# PIC32CK1025GC00100 device description
Architecture: CORTEX-M33; Family: PIC32CK; Series: PIC32CKGC00
Registers are 32-bit, read-write, reset 0x0 unless marked. A register's access mark holds for its fields unless they carry their own. Offsets are from the block's base; [hi:lo] are bit positions; lines under a group give offsets from that group; {n}, {i} and the like mark numbered series; 'fields as' and 'values as' point back to an identical list; <NAME> marks a mode.

## SIG — Software Interrupt Generation
Instances: SIG 0xE000EF00
0x00 STIR wo reset not defined — Software Triggered Interrupt Register
  [8:0] INTID — Interrupt ID to be pended

## SQI_DESCRIPTOR — Polaris Serial Quad Interface SIB
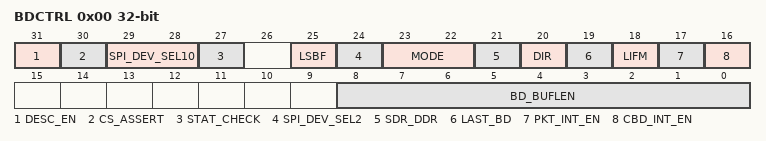
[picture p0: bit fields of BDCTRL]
0x00 BDCTRL reset not defined — Buffer Descriptor Control Register
  [31] DESC_EN — Descriptor Enable
  [30] CS_ASSERT — Chip Select Assert/Deassert
  [29:28] SPI_DEV_SEL10 — SPI Device Select bits 1:0
  [27] STAT_CHECK — Status Check
  [25] LSBF — Data format on SPI Data Lanes
  [24] SPI_DEV_SEL2 — SPI Device Select bit 2
  [23:22] MODE — Based on the mode, the controller has to transmit or receive the data in one or two or 4 lanes
  [21] SDR_DDR — SDR or DDR mode
  [20] DIR — Direction of data transfer.
  [19] LAST_BD — Last Buffer Descriptors.
  [18] LIFM — Indicates last data of the packet.
  [17] PKT_INT_EN — Generate Interrupt after processing the current buffer descriptor, if it is the end of the packet.
  [16] CBD_INT_EN — Generate Interrupt after processing the current buffer descriptor
  [8:0] BD_BUFLEN — Buffer Descriptor Length
0x04 BDSTATUS reset not defined — Buffer Descriptor Status Register
0x08 BDADDR reset not defined — Buffer Descriptor Address Register
0x0C BDNXTPTR reset not defined — Buffer Descriptor Next Pointer Register

## SysTick — SysTick Timer
Instances: SysTick 0xE000E010
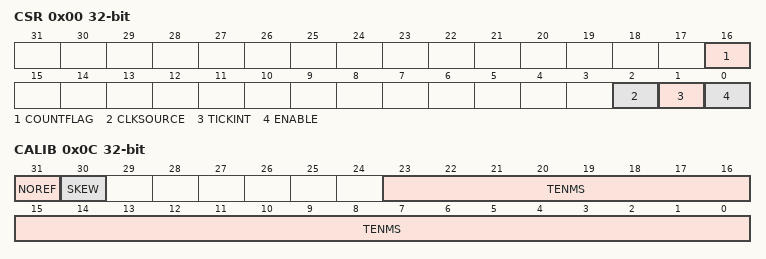
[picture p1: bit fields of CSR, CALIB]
0x00 CSR reset not defined — SysTick Control and Status Register
  [16] COUNTFLAG
  [2] CLKSOURCE — Clock source
  [1] TICKINT — Tick interrupt
  [0] ENABLE — SysTick enable
0x04 RVR reset not defined — SysTick Reload Value Register
  [24] RELOAD — Counter reload value
0x08 CVR reset not defined — SysTick Current Value Register
  [24] CURRENT — Current counter value
0x0C CALIB ro reset not defined — SysTick Calibration Value Register
  [31] NOREF — No reference
  [30] SKEW
  [23:0] TENMS — Ten milliseconds

## TRAM — TrustRAM
Instances: TRAM 0x4401E000
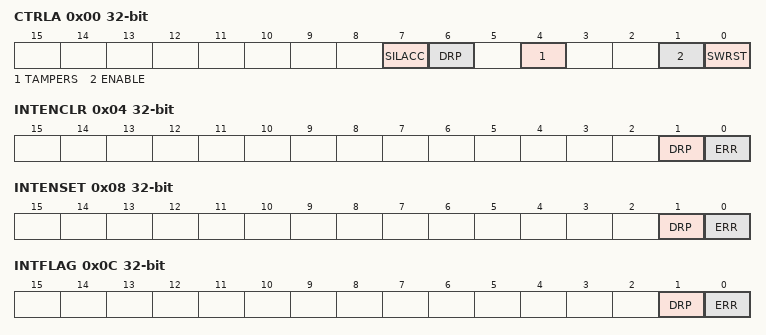
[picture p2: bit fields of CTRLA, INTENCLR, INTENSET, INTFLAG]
0x00 CTRLA — Control
  [7] SILACC — Silent Access
  [6] DRP — Data Remanence Prevention
  [4] TAMPERS — Tamper Erase
  [1] ENABLE
  [0] SWRST — Software Reset
0x04 INTENCLR (atomic clear) — Interrupt Enable Clear
  [1] DRP — Data Remanence Prevention Ended Interrupt Enable
  [0] ERR — TrustRAM Readout Error Interrupt Enable
0x08 INTENSET (atomic set) — Interrupt Enable Set
  fields as INTENCLR
0x0C INTFLAG (atomic clear) — Interrupt Flag Status and Clear
  [1] DRP — Data Remanence Prevention Ended
  [0] ERR — TrustRAM Readout Error
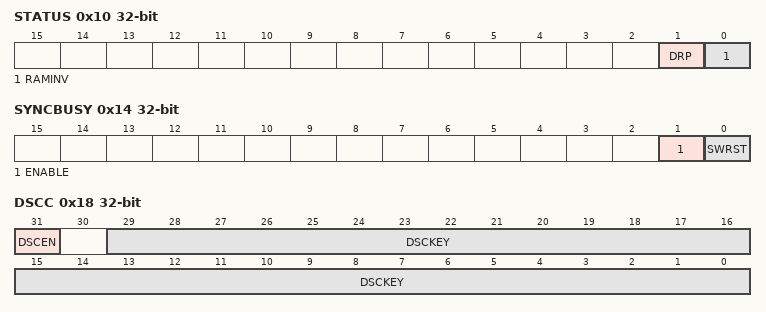
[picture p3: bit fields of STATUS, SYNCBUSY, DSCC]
0x10 STATUS ro
  [1] DRP — Data Remanence Prevention Ongoing
  [0] RAMINV — RAM Inversion Bit
0x14 SYNCBUSY ro — Synchronization Busy Status
  [1] ENABLE — Enable Busy
  [0] SWRST — Software Reset Busy
0x18 DSCC wo — Data Scramble Control
  [31] DSCEN — Data Scramble Enable
  [29:0] DSCKEY — Data Scramble Key
0x1C PERMW wo — Permutation Write
  [2:0] DATA — Permutation Scrambler Data Input
0x20 PERMR ro — Permutation Read
  [2:0] DATA — Permutation Scrambler Data Output
{0x1000+4i} RAM[{i}] (i=0..2047) — TrustRAM
  [31:0] DATA — Trust RAM Data

## TRNG — True Random Generator
Instances: TRNG 0x45024000
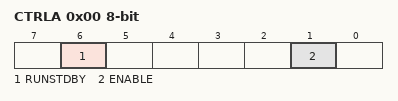
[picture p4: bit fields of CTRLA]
0x00 CTRLA 8-bit — Control A
  [6] RUNSTDBY — Run in Standby
  [1] ENABLE
0x04 EVCTRL 8-bit — Event Control
  [0] DATARDYEO — Data Ready Event Output
0x08 INTENCLR 8-bit (atomic clear) — Interrupt Enable Clear
  [0] DATARDY — Data Ready Interrupt Enable
0x09 INTENSET 8-bit (atomic set) — Interrupt Enable Set
  [0] DATARDY — Data Ready Interrupt Enable
0x0A INTFLAG 8-bit (atomic clear) — Interrupt Flag Status and Clear
  [0] DATARDY — Data Ready Interrupt Flag
0x20 DATA ro reset not defined — Output Data

## USB_DESCRIPTOR — Full-Speed Universal Serial Bus
Modes: DEVICE when USB.CTRLA.MODE=0 (USB is Device); HOST when USB.CTRLA.MODE=1 (USB is Host)
{0x0+0x10*i} DEVICE_DESC_BANK[{i}] (i=0..1) <DEVICE> group
  0x00 ADDR <DEVICE> reset not defined — DEVICE_DESC_BANK Endpoint Bank, Adress of Data Buffer
    [31:0] ADDR — Adress of data buffer
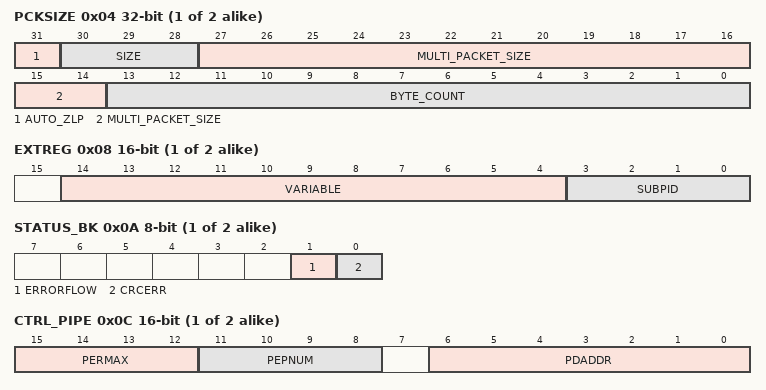
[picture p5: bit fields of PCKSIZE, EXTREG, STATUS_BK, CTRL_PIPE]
  0x04 PCKSIZE <DEVICE> reset not defined — DEVICE_DESC_BANK Endpoint Bank, Packet Size
    [31] AUTO_ZLP — Automatic Zero Length Packet
    [30:28] SIZE — Enpoint size
    [27:14] MULTI_PACKET_SIZE — Multi Packet In or Out size
    [13:0] BYTE_COUNT
  0x08 EXTREG <DEVICE> 16-bit reset not defined — DEVICE_DESC_BANK Endpoint Bank, Extended
    [14:4] VARIABLE — Variable field send with extended token
    [3:0] SUBPID — SUBPID field send with extended token
  0x0A STATUS_BK <DEVICE> 8-bit reset not defined — DEVICE_DESC_BANK Enpoint Bank, Status of Bank
    [1] ERRORFLOW — Error Flow Status
    [0] CRCERR — CRC Error Status
{0x0+0x10*i} HOST_DESC_BANK[{i}] (i=0..1) <HOST> group
  0x00 ADDR <HOST> reset not defined — HOST_DESC_BANK Host Bank, Adress of Data Buffer
    [31:0] ADDR — Adress of data buffer
  0x04 PCKSIZE <HOST> reset not defined — HOST_DESC_BANK Host Bank, Packet Size
    [31] AUTO_ZLP — Automatic Zero Length Packet
    [30:28] SIZE — Pipe size
    [27:14] MULTI_PACKET_SIZE — Multi Packet In or Out size
    [13:0] BYTE_COUNT
  0x08 EXTREG <HOST> 16-bit reset not defined — HOST_DESC_BANK Host Bank, Extended
    fields as DEVICE_DESC_BANK[0]<DEVICE>.EXTREG<DEVICE>
  0x0A STATUS_BK <HOST> 8-bit reset not defined — HOST_DESC_BANK Host Bank, Status of Bank
    [1] ERRORFLOW — Error Flow Status
    [0] CRCERR — CRC Error Status
  0x0C CTRL_PIPE <HOST> 16-bit — HOST_DESC_BANK Host Bank, Host Control Pipe
    [15:12] PERMAX — Pipe Error Max Number
    [11:8] PEPNUM — Pipe Endpoint Number
    [6:0] PDADDR — Pipe Device Adress
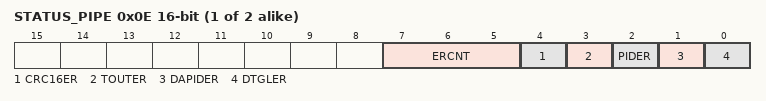
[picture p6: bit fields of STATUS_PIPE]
  0x0E STATUS_PIPE <HOST> 16-bit reset not defined — HOST_DESC_BANK Host Bank, Host Status Pipe
    [7:5] ERCNT — Pipe Error Count
    [4] CRC16ER — CRC16 Error
    [3] TOUTER — Time Out Error
    [2] PIDER — PID Error
    [1] DAPIDER — Data PID Error
    [0] DTGLER — Data Toggle Error

## WDT — Watchdog Timer
Instances: WDT 0x44016000
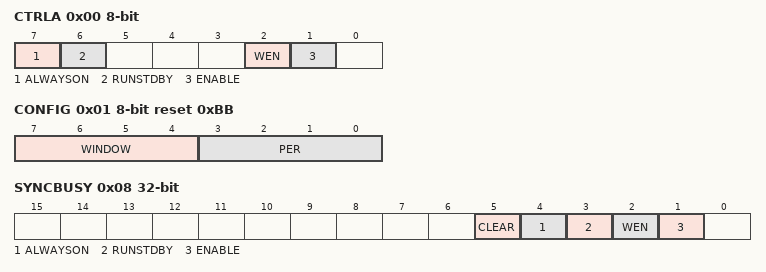
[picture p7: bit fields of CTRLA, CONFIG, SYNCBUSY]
0x00 CTRLA 8-bit (WSYNC) — Control
  [7] ALWAYSON
  [6] RUNSTDBY — Run During Standby
  [2] WEN — Watchdog Timer Window Mode Enable
  [1] ENABLE
0x01 CONFIG 8-bit reset 0xBB — Configuration
  [7:4] WINDOW — Window Mode Time-Out Period
    0=CYC8 (8 clock cycles); 1=CYC16 (16 clock cycles); 2=CYC32 (32 clock cycles); 3=CYC64 (64 clock cycles); 4=CYC128 (128 clock cycles); 5=CYC256 (256 clock cycles); 6=CYC512 (512 clock cycles); 7=CYC1024 (1024 clock cycles); 8=CYC2048 (2048 clock cycles); 9=CYC4096 (4096 clock cycles); 10=CYC8192 (8192 clock cycles); 11=CYC16384 (16384 clock cycles)
  [3:0] PER — Time-Out Period
    values as WINDOW
0x02 EWCTRL 8-bit reset 0xB — Early Warning Interrupt Control
  [3:0] EWOFFSET — Early Warning Interrupt Time Offset
    values as CONFIG.WINDOW
0x04 INTENCLR 8-bit (atomic clear) — Interrupt Enable Clear
  [0] EW — Early Warning Interrupt Enable
0x05 INTENSET 8-bit (atomic set) — Interrupt Enable Set
  [0] EW — Early Warning Interrupt Enable
0x06 INTFLAG 8-bit (atomic clear) — Interrupt Flag Status and Clear
  [0] EW — Early Warning
0x08 SYNCBUSY ro — Synchronization Busy
  [5] CLEAR — Clear Synchronization Busy
  [4] ALWAYSON — Always-On Synchronization Busy
  [3] RUNSTDBY — Run During Standby Synchronization Busy
  [2] WEN — Window Enable Synchronization Busy
  [1] ENABLE — Enable Synchronization Busy
0x0C CLEAR 8-bit wo (WSYNC)
  [7:0] CLEAR — Watchdog Clear
    165=KEY (Clear Key)
